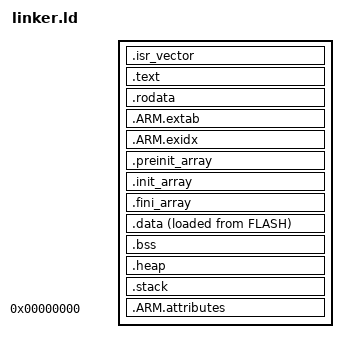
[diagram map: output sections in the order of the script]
/* Generated by keil-bridge for ${device}; do not edit.
 * Change memory, stack and heap sizes in keil-bridge.toml and run `keil-bridge regen`. */

ENTRY(Reset_Handler)

__stack_size = ${stack_size};
__heap_size = ${heap_size};

MEMORY
{
  FLASH (rx) : ORIGIN = ${flash_origin}, LENGTH = ${flash_size}
  RAM (rw)   : ORIGIN = ${ram_origin}, LENGTH = ${ram_size}
}

/* The stack starts at the top of RAM and grows down. */
_estack = ORIGIN(RAM) + LENGTH(RAM);

SECTIONS
{
  .isr_vector :
  {
    . = ALIGN(4);
    KEEP(*(.isr_vector))
    . = ALIGN(4);
  } >FLASH

  .text :
  {
    . = ALIGN(4);
    *(.text)
    *(.text*)
    *(.glue_7)
    *(.glue_7t)
    *(.eh_frame)
    KEEP(*(.init))
    KEEP(*(.fini))
    . = ALIGN(4);
  } >FLASH

  .rodata :
  {
    . = ALIGN(4);
    *(.rodata)
    *(.rodata*)
    . = ALIGN(4);
  } >FLASH

  .ARM.extab : { *(.ARM.extab* .gnu.linkonce.armextab.*) } >FLASH
  .ARM.exidx :
  {
    __exidx_start = .;
    *(.ARM.exidx* .gnu.linkonce.armexidx.*)
    __exidx_end = .;
  } >FLASH

  .preinit_array (READONLY) :
  {
    PROVIDE_HIDDEN(__preinit_array_start = .);
    KEEP(*(.preinit_array*))
    PROVIDE_HIDDEN(__preinit_array_end = .);
  } >FLASH
  .init_array (READONLY) :
  {
    PROVIDE_HIDDEN(__init_array_start = .);
    KEEP(*(SORT(.init_array.*)))
    KEEP(*(.init_array*))
    PROVIDE_HIDDEN(__init_array_end = .);
  } >FLASH
  .fini_array (READONLY) :
  {
    PROVIDE_HIDDEN(__fini_array_start = .);
    KEEP(*(SORT(.fini_array.*)))
    KEEP(*(.fini_array*))
    PROVIDE_HIDDEN(__fini_array_end = .);
  } >FLASH

  _sidata = LOADADDR(.data);
  .data :
  {
    . = ALIGN(4);
    _sdata = .;
    *(.data)
    *(.data*)
    . = ALIGN(4);
    _edata = .;
  } >RAM AT> FLASH

  .bss (NOLOAD) :
  {
    . = ALIGN(4);
    _sbss = .;
    __bss_start__ = _sbss;
    *(.bss)
    *(.bss*)
    *(COMMON)
    . = ALIGN(4);
    _ebss = .;
    __bss_end__ = _ebss;
  } >RAM

  .heap (NOLOAD) :
  {
    . = ALIGN(8);
    __heap_base = .;
    PROVIDE(end = .);
    . = . + __heap_size;
    __heap_limit = .;
  } >RAM

  /* Only reserves room so that the link fails when the stack does not fit. */
  .stack (NOLOAD) :
  {
    . = ALIGN(8);
    . = . + __stack_size;
  } >RAM

  .ARM.attributes 0 : { *(.ARM.attributes) }
}
